AUTOSAR XML (schema 00046)
package /Runnable_Lab2
  sender receiver interface SRI_Output
    data SumResult: type=uint32
  sender receiver interface SRI_Inputs
    data Val1: type=uint16
    data Val2: type=uint16
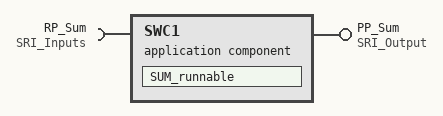
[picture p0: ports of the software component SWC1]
  application sw component type SWC1
    provide port PP_Sum: provided-interface=SRI_Output
    require port RP_Sum: required-interface=SRI_Inputs
    behavior SWC1_Behavior
      runnable SUM_runnable: symbol=SUM
        data-write-access:
          access SUMResult_Data: accessed-variable=PP_Sum.SumResult
        data-read-access:
          access VAL1_DATA: accessed-variable=RP_Sum.Val1
          access VAL2_DATA: accessed-variable=RP_Sum.Val2
